# PIC32MX775F256H device description
Architecture: MIPS; Family: PIC32MX; Series: PIC32MX
Registers are 32-bit, read-write, no defined reset value unless marked. A register's access mark holds for its fields unless they carry their own. Offsets are from the block's base; [hi:lo] are bit positions; lines under a group give offsets from that group; {n}, {i} and the like mark numbered series.

## INT
Instances: INT 0x1f881000 in periph2
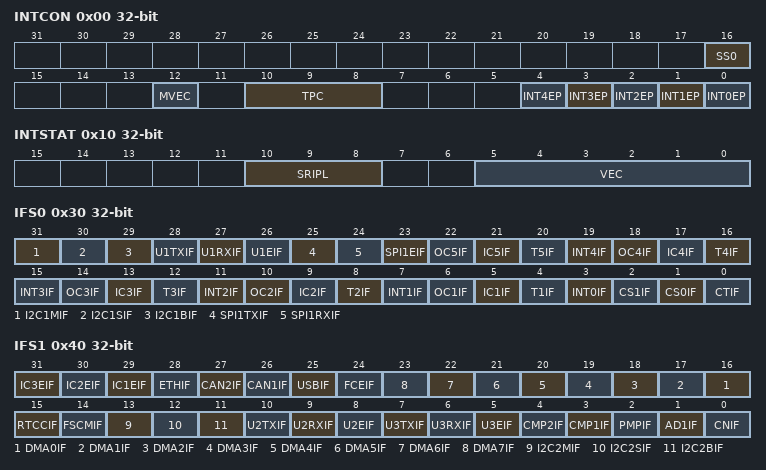
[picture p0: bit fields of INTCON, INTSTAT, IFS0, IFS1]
0x00 INTCON — Interrupt Control Register
  [16] SS0
    1=Single vector is presented with a shadow register set; 0=Single vector is not presented with a shadow register set
  [12] MVEC — Multi Vector Configuration bit
    1=Interrupt controller configured for Multi-vectored mode; 0=Interrupt controller configured for Single-vectored mode
  [10:8] TPC — Interrupt Proximity Timer Control bits
    {v}=Interrupts of group priority {v} or lower start the Interrupt Proximity timer (v=2..7); 1=Interrupts of group priority 1 start the Interrupt Proximity timer; 0=Disables Interrupt Proximity timer
  [n] INT{n}EP (n=0..4) — External Interrupt {n} Edge
    1=Rising edge; 0=Falling edge
0x10 INTSTAT — Interrupt Status Register
  [10:8] SRIPL — Requested Priority Level bits
    {v}=The priority level of the latest interrupt presented to the CPU is {v} (v=0..7)
  [5:0] VEC — Interrupt Vector bits
    {v}=The interrupt vector that is presented to the CPU is {v} (v=0..31)
0x20 IPTMR
0x30 IFS0 — Interrupt Flag Status Register 0
  [31] I2C1MIF, [30] I2C1SIF, [29] I2C1BIF, [28] U1TXIF, [27] U1RXIF, [26] U1EIF, [25] SPI1TXIF, [24] SPI1RXIF, [23] SPI1EIF, [4n+2] OC{n}IF (n=1..5), [4n+1] IC{n}IF (n=1..5), [4n] T{n}IF (n=1..5), [4n+3] INT{n}IF (n=0..4), [2] CS1IF, [1] CS0IF, [0] CTIF
0x40 IFS1 — Interrupt Flag Status Register 1
  [31] IC3EIF, [30] IC2EIF, [29] IC1EIF, [28] ETHIF, [27] CAN2IF, [26] CAN1IF, [25] USBIF, [24] FCEIF, [n+16] DMA{n}IF (n=0..7), [15] RTCCIF, [14] FSCMIF, [13] I2C2MIF, [12] I2C2SIF, [11] I2C2BIF, [10] U2TXIF, [9] U2RXIF, [8] U2EIF, [7] U3TXIF, [6] U3RXIF, [5] U3EIF, [4] CMP2IF, [3] CMP1IF, [2] PMPIF, [1] AD1IF, [0] CNIF
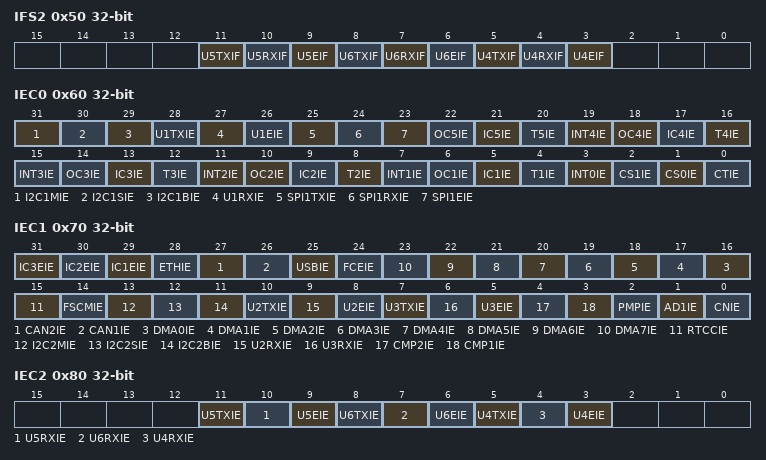
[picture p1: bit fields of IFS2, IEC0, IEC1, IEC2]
0x50 IFS2 — Interrupt Flag Status Register 2
  [11] U5TXIF, [10] U5RXIF, [9] U5EIF, [8] U6TXIF, [7] U6RXIF, [6] U6EIF, [5] U4TXIF, [4] U4RXIF, [3] U4EIF
0x60 IEC0 — Interrupt Enable Control Register 0
  [31] I2C1MIE, [30] I2C1SIE, [29] I2C1BIE, [28] U1TXIE, [27] U1RXIE, [26] U1EIE, [25] SPI1TXIE, [24] SPI1RXIE, [23] SPI1EIE, [4n+2] OC{n}IE (n=1..5), [4n+1] IC{n}IE (n=1..5), [4n] T{n}IE (n=1..5), [4n+3] INT{n}IE (n=0..4), [2] CS1IE, [1] CS0IE, [0] CTIE
0x70 IEC1 — Interrupt Enable Control Register 1
  [31] IC3EIE, [30] IC2EIE, [29] IC1EIE, [28] ETHIE, [27] CAN2IE, [26] CAN1IE, [25] USBIE, [24] FCEIE, [n+16] DMA{n}IE (n=0..7), [15] RTCCIE, [14] FSCMIE, [13] I2C2MIE, [12] I2C2SIE, [11] I2C2BIE, [10] U2TXIE, [9] U2RXIE, [8] U2EIE, [7] U3TXIE, [6] U3RXIE, [5] U3EIE, [4] CMP2IE, [3] CMP1IE, [2] PMPIE, [1] AD1IE, [0] CNIE
0x80 IEC2 — Interrupt Enable Control Register 2
  [11] U5TXIE, [10] U5RXIE, [9] U5EIE, [8] U6TXIE, [7] U6RXIE, [6] U6EIE, [5] U4TXIE, [4] U4RXIE, [3] U4EIE
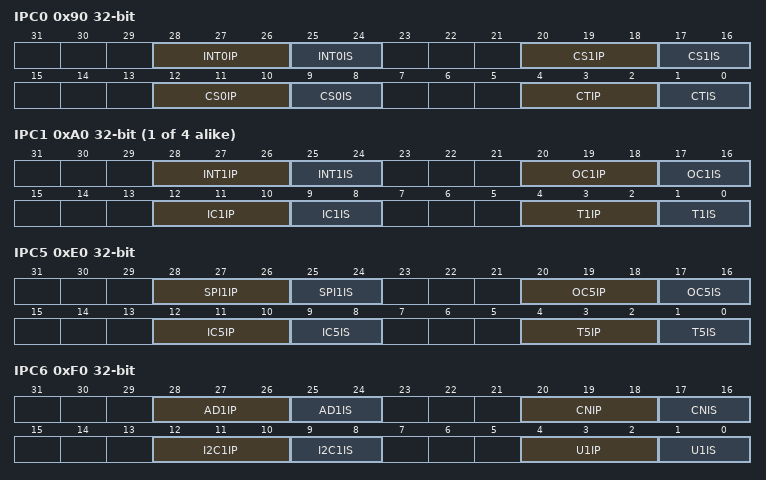
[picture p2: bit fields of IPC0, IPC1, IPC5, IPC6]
0x90 IPC0 — Interrupt Priority Control Register 0
  [28:26] INT0IP, [25:24] INT0IS, [20:18] CS1IP, [17:16] CS1IS, [12:10] CS0IP, [9:8] CS0IS, [4:2] CTIP, [1:0] CTIS
{0x90+0x10*i} IPC{i} (i=1..4) — Interrupt Priority Control Register {i}
  [28:26] INT{i}IP, [25:24] INT{i}IS, [20:18] OC{i}IP, [17:16] OC{i}IS, [12:10] IC{i}IP, [9:8] IC{i}IS, [4:2] T{i}IP, [1:0] T{i}IS
0xE0 IPC5 — Interrupt Priority Control Register 5
  [28:26] SPI1IP, [25:24] SPI1IS, [20:18] OC5IP, [17:16] OC5IS, [12:10] IC5IP, [9:8] IC5IS, [4:2] T5IP, [1:0] T5IS
0xF0 IPC6 — Interrupt Priority Control Register 6
  [28:26] AD1IP, [25:24] AD1IS, [20:18] CNIP, [17:16] CNIS, [12:10] I2C1IP, [9:8] I2C1IS, [4:2] U1IP, [1:0] U1IS
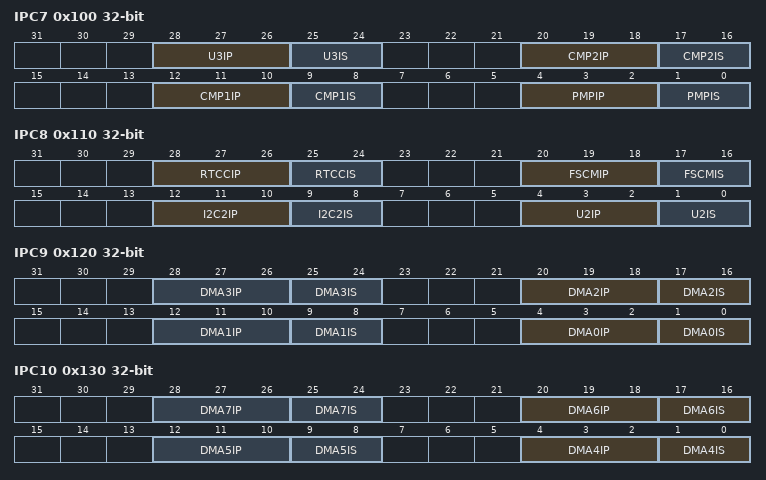
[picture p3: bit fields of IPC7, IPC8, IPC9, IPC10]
0x100 IPC7 — Interrupt Priority Control Register 7
  [28:26] U3IP, [25:24] U3IS, [20:18] CMP2IP, [17:16] CMP2IS, [12:10] CMP1IP, [9:8] CMP1IS, [4:2] PMPIP, [1:0] PMPIS
0x110 IPC8 — Interrupt Priority Control Register 8
  [28:26] RTCCIP, [25:24] RTCCIS, [20:18] FSCMIP, [17:16] FSCMIS, [12:10] I2C2IP, [9:8] I2C2IS, [4:2] U2IP, [1:0] U2IS
0x120 IPC9 — Interrupt Priority Control Register 9
  [8n+4:8n+2] DMA{n}IP (n=0..3), [8n+1:8n] DMA{n}IS (n=0..3)
0x130 IPC10 — Interrupt Priority Control Register 10
  [8n-28:8n-30] DMA{n}IP (n=4..7), [8n-31:8n-32] DMA{n}IS (n=4..7)
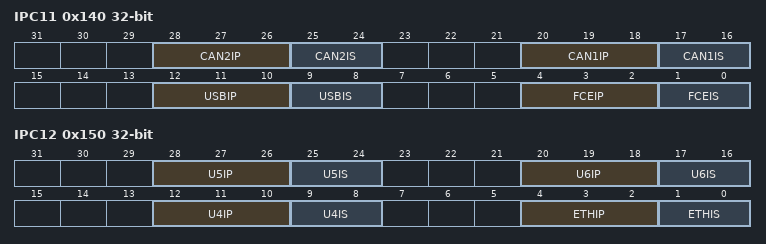
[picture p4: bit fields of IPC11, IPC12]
0x140 IPC11 — Interrupt Priority Control Register 11
  [28:26] CAN2IP, [25:24] CAN2IS, [20:18] CAN1IP, [17:16] CAN1IS, [12:10] USBIP, [9:8] USBIS, [4:2] FCEIP, [1:0] FCEIS
0x150 IPC12 — Interrupt Priority Control Register 12
  [28:26] U5IP, [25:24] U5IS, [20:18] U6IP, [17:16] U6IS, [12:10] U4IP, [9:8] U4IS, [4:2] ETHIP, [1:0] ETHIS

## Notices in the file
Copyright (c) 2019 Microchip Technology Inc.
SPDX-License-Identifier: Apache-2.0
Licensed under the Apache License, Version 2.0 (the "License");
you may not use this file except in compliance with the License.
You may obtain a copy of the License at
http://www.apache.org/licenses/LICENSE-2.0
Unless required by applicable law or agreed to in writing, software
distributed under the License is distributed on an "AS IS" BASIS,
WITHOUT WARRANTIES OR CONDITIONS OF ANY KIND, either express or implied.
See the License for the specific language governing permissions and
limitations under the License.
